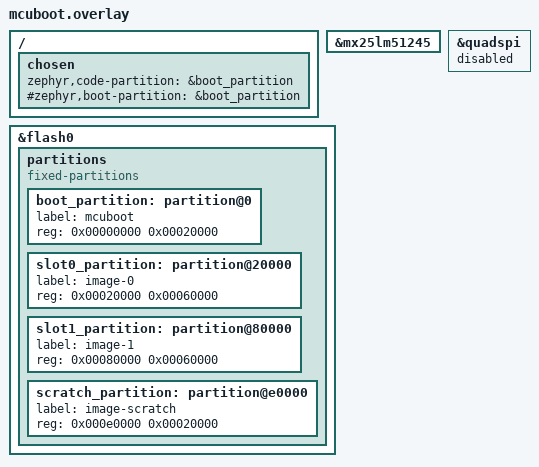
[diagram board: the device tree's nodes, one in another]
/ {
	chosen {
		zephyr,code-partition = &boot_partition;
		#zephyr,boot-partition = &boot_partition;
	};
};

&mx25lm51245 {
	/delete-node/ partitions;
};

&quadspi {
	status = "disabled";
};

/* Dahili Flash (Flash0) - 128KB Sektör Hizalaması */
&flash0 {
	partitions {
		compatible = "fixed-partitions";
		#address-cells = <1>;
		#size-cells = <1>;

		/* STM32H735 Sektör Boyutu: 128KB */
		/* Bootloader F7'deki gibi 64KB OLAMAZ. 128KB (0x20000) olmak zorunda */
		
		boot_partition: partition@0 {
			label = "mcuboot";
			reg = <0x00000000 0x00020000>; /* 128KB (1 Sektör) */
		};

		/* Slot 0 - Uygulama */
		slot0_partition: partition@20000 {
			label = "image-0";
			reg = <0x00020000 0x00060000>; /* 384KB (3 Sektör) */
		};

		/* Slot 1 - Güncelleme (Dahili flasha sığdırmak için) */
		/* H735G 1MB Flash'a sahiptir. Yer darlığı çekebilirsin.
		   Eğer sığmıyorsa Slot1 harici flasha taşınmalı. 
		   Şimdilik dahili örnek: */
		slot1_partition: partition@80000 {
			label = "image-1";
			reg = <0x00080000 0x00060000>; /* 384KB (3 Sektör) */
		};

		/* Scratch - 128KB */
		scratch_partition: partition@e0000 {
			label = "image-scratch";
			reg = <0x000e0000 0x00020000>; /* 128KB (1 Sektör) */
		};
	};
};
